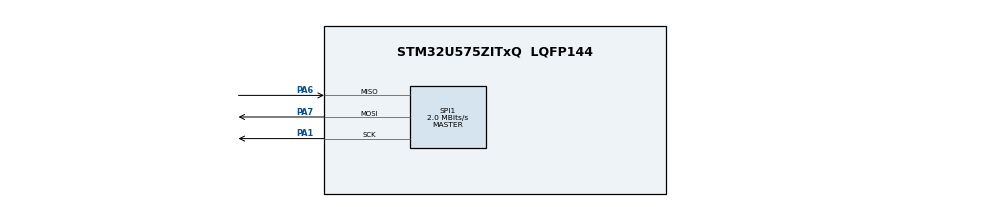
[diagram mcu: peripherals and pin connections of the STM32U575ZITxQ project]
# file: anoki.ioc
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CORTEX_M33_NS.userName=CORTEX_M33
Mcu.Family=STM32U5
Mcu.Name=STM32U575ZITxQ
Mcu.Package=LQFP144
NVIC.PriorityGroup=NVIC_PRIORITYGROUP_4
PA1.Mode=Full_Duplex_Master
PA1.Signal=SPI1_SCK
PA13\ (JTMS/SWDIO).Mode=Serial_Wire
PA13\ (JTMS/SWDIO).Signal=DEBUG_JTMS-SWDIO
PA14\ (JTCK/SWCLK).Mode=Serial_Wire
PA14\ (JTCK/SWCLK).Signal=DEBUG_JTCK-SWCLK
PA6.Mode=Full_Duplex_Master
PA6.Signal=SPI1_MISO
PA7.Mode=Full_Duplex_Master
PA7.Signal=SPI1_MOSI
ProjectManager.HeapSize=0x200
ProjectManager.StackSize=0x400
ProjectManager.TargetToolchain=CMake
RCC.ADCFreq_Value=16000000
RCC.EPOD_VALUE=4000000
RCC.HSE_VALUE=16000000
RCC.HSI48_VALUE=48000000
RCC.HSI_VALUE=16000000
RCC.LSE_VALUE=32768
RCC.LSIDIV_VALUE=32000
RCC.MSI_VALUE=4000000
RCC.USBFreq_Value=48000000
RCC.VCOOutputFreq_Value=516000000
SPI1.CalculateBaudRate=2.0 MBits/s
SPI1.DataSize=SPI_DATASIZE_8BIT
SPI1.Direction=SPI_DIRECTION_2LINES
SPI1.Mode=SPI_MODE_MASTER
SPI1.VirtualType=VM_MASTER
VP_LPBAMQUEUE_VS_QUEUE.Mode=QUEUEMODE
VP_LPBAM_VS_SIG1.Mode=SmartRun
VP_LPBAM_VS_SIG4.Mode=LPDMA1
VP_MEMORYMAP_VS_MEMORYMAP.Mode=CurAppReg
VP_PWR_VS_LPOM.Mode=PowerOptimisation
VP_PWR_VS_SECSignals.Mode=Security/Privilege
board=custom

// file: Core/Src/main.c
/* USER CODE BEGIN Header */
/**
  ******************************************************************************
  * @file           : main.c
  * @brief          : Main program body
  ******************************************************************************
  * @attention
  *
  * Copyright (c) 2025 STMicroelectronics.
  * All rights reserved.
  *
  * This software is licensed under terms that can be found in the LICENSE file
  * in the root directory of this software component.
  * If no LICENSE file comes with this software, it is provided AS-IS.
  *
  ******************************************************************************
  */
/* USER CODE END Header */
#include "main.h"
#include "spi.h"
#include "gpio.h"

/* USER CODE BEGIN PV */

//todo fix cmake
//todo add openocd
//todo integrate drivers to files from mains

/* USER CODE END PV */

void SystemClock_Config(void);

int main(void)
{

  /* MCU Configuration--------------------------------------------------------*/

  /* Reset of all peripherals, Initializes the Flash interface and the Systick. */
  HAL_Init();

  /* Configure the system clock */
  SystemClock_Config();

  /* Initialize all configured peripherals */
  MX_GPIO_Init();
  MX_SPI1_Init();

  /* Infinite loop */
  while (1)
  {

  }
}

void SystemClock_Config(void)
{
  RCC_OscInitTypeDef RCC_OscInitStruct = {0};
  RCC_ClkInitTypeDef RCC_ClkInitStruct = {0};

  /** Configure the main internal regulator output voltage
  */
  if (HAL_PWREx_ControlVoltageScaling(PWR_REGULATOR_VOLTAGE_SCALE4) != HAL_OK)
  {
    Error_Handler();
  }

  /** Initializes the CPU, AHB and APB buses clocks
  */
  RCC_OscInitStruct.OscillatorType = RCC_OSCILLATORTYPE_MSI;
  RCC_OscInitStruct.MSIState = RCC_MSI_ON;
  RCC_OscInitStruct.MSICalibrationValue = RCC_MSICALIBRATION_DEFAULT;
  RCC_OscInitStruct.MSIClockRange = RCC_MSIRANGE_4;
  RCC_OscInitStruct.PLL.PLLState = RCC_PLL_NONE;
  if (HAL_RCC_OscConfig(&RCC_OscInitStruct) != HAL_OK)
  {
    Error_Handler();
  }

  /** Initializes the CPU, AHB and APB buses clocks
  */
  RCC_ClkInitStruct.ClockType = RCC_CLOCKTYPE_HCLK|RCC_CLOCKTYPE_SYSCLK
                              |RCC_CLOCKTYPE_PCLK1|RCC_CLOCKTYPE_PCLK2
                              |RCC_CLOCKTYPE_PCLK3;
  RCC_ClkInitStruct.SYSCLKSource = RCC_SYSCLKSOURCE_MSI;
  RCC_ClkInitStruct.AHBCLKDivider = RCC_SYSCLK_DIV1;
  RCC_ClkInitStruct.APB1CLKDivider = RCC_HCLK_DIV1;
  RCC_ClkInitStruct.APB2CLKDivider = RCC_HCLK_DIV1;
  RCC_ClkInitStruct.APB3CLKDivider = RCC_HCLK_DIV1;

  if (HAL_RCC_ClockConfig(&RCC_ClkInitStruct, FLASH_LATENCY_0) != HAL_OK)
  {
    Error_Handler();
  }
}

void Error_Handler(void)
{
  __disable_irq();
  while (1)
  {
  }
}
